# STM32H7RSxx register map
File version: 0.2
CPU: CM7 r0p1, little endian, MPU, FPU, 4 interrupt priority bits
Registers are 32-bit, read-write, reset 0x0 unless marked. A register's access mark holds for its fields unless they carry their own. Offsets are from the block's base; [hi:lo] are bit positions; lines under a group give offsets from that group; 'fields as' and 'values as' point back to an identical list.

## DCMIPP — Digital camera interface pixel pipeline
Base 0x50002000
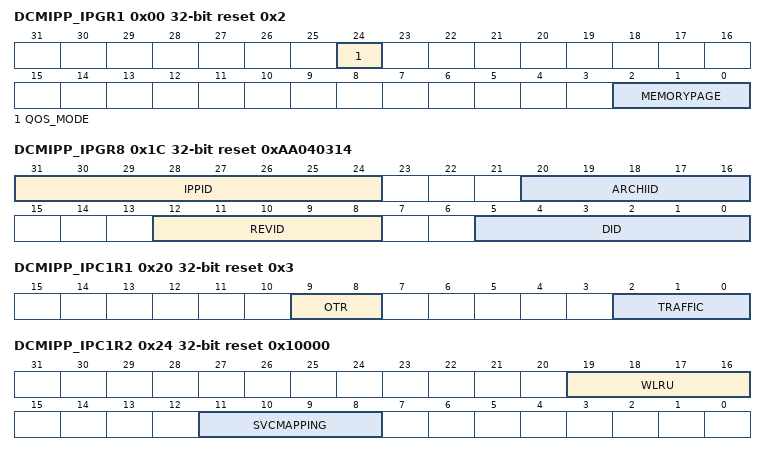
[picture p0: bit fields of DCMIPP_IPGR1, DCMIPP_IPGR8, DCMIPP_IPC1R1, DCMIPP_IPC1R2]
0x00 DCMIPP_IPGR1 reset 0x2 — DCMIPP IP-Plug global register 1
  [24] QOS_MODE — Quality of service Set of functions enabling to build and configure an architecture able to meet bandwidth and latency requirements.
  [2:0] MEMORYPAGE — Memory page size, as power of 2 of 64-byte units:
    0=64 bytes; 1=128 bytes
0x04 DCMIPP_IPGR2 — DCMIPP IP-Plug global register 2
  [0] PSTART — Request to lock the IP-Plug, to allow reconfiguration. PSTART must be reset to 0 after configuration is completed, to restart the IP-Plug.
    0=No lock requested, IP-Plug runs on demand by background HW; 1=Lock requested: IP-Plug freezes shortly (see IDLE bit when lock is active)
0x08 DCMIPP_IPGR3 ro reset 0x1 — DCMIPP IP-Plug global register 3
  [0] IDLE — Status of IP-Plug IDLE is set some time after a request by setting PSTART at 1, and reset by resetting PSTART at 0.
    0=IP-Plug is running (on demand by background HW); 1=IP-Plug is currently locked and can be reconfigured
0x1C DCMIPP_IPGR8 ro reset 0xAA040314 — DCMIPP IP-Plug identification register
  [31:24] IPPID — IP identifier (0xAA)
  [20:16] ARCHIID — Architecture identifier (0x04)
  [12:8] REVID — Revision identifier (0x03)
  [5:0] DID — Division identifier (0x14)
0x20 DCMIPP_IPC1R1 reset 0x3 — DCMIPP IP-Plug Clientx register 1
  [9:8] OTR — Maximum outstanding transactions ... Other values are not allowed.
    0=Disabled. No outstanding transaction limitation (except via FIFO size); 1=Maximum two outstanding transactions ongoing
  [2:0] TRAFFIC — Burst size as power of 2 of 8-byte units Other values: Reserved
    0=8 bytes; 1=16 bytes
0x24 DCMIPP_IPC1R2 reset 0x10000 — DCMIPP IP-Plug Clientx register 2
  [19:16] WLRU — Ratio for WLRU[3:0] arbitration A client gets a portion of the total bandwidth = Ratio(client) / Sum(all ratio) ...
    0=Ratio part = 1; 1=Ratio part = 2
  [11:8] SVCMAPPING — Non-user, must be kept at reset value.
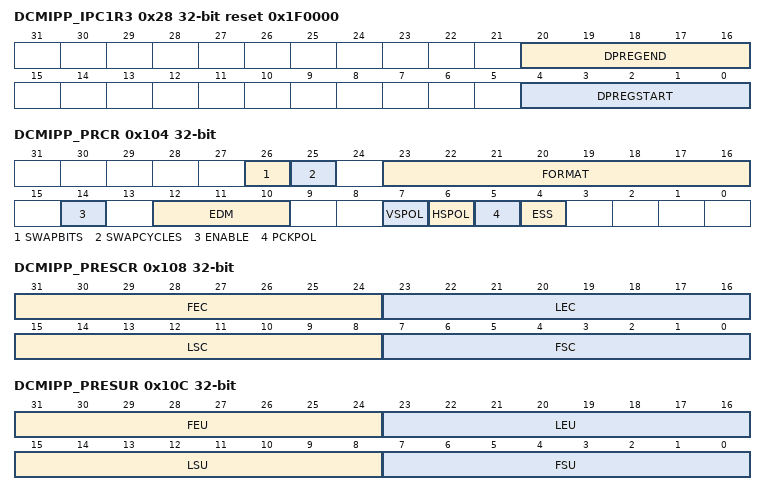
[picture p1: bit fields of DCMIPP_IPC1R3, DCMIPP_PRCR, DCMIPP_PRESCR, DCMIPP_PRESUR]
0x28 DCMIPP_IPC1R3 reset 0x1F0000 — DCMIPP IP-Plug Clientx register 3
  [20:16] DPREGEND — End word (AXI width = 64 bits) of the FIFO of Clientx. The addressed word is included in the FIFO, so that next DPREGSTART is DPREGEND + 1.
  [4:0] DPREGSTART — Start word (AXI width = 64 bits) of the FIFO of Clientx.
0x104 DCMIPP_PRCR — DCMIPP parallel interface control register
  [26] SWAPBITS — Swap LSB vs. MSB within each received component
    0=As received; 1=Swapped MSB vs. LSB
  [25] SWAPCYCLES — Swap data (cycle 0 vs. cycle 1) for pixels received on two cycles The swap must not be activated by software for pixels received in one or three cycles.
    0=Default; 1=Swap active: the data of cycle 1 is used before the data of cycle 0
  [23:16] FORMAT — Other values: data are captured and output as-is only through the data/dump pipeline (for example JPEG or byte input format). The monochrome Y input is inserted in the pipe as YUV pixels, with the U and V components set to neutral, to represent a grey color.
    30=YUV422; 34=RGB565; 36=RGB888 (= YUV444); 42=RAW8; 43=RAW10; 44=RAW12; 45=RAW14; 74=monochrome 8-bit; 75=monochrome 10-bit; 76=monochrome 12-bit; 77=monochrome 14-bit; 90=byte stream (JPEG, compressed video)
  [14] ENABLE — Parallel interface enable The parallel interface configuration registers must be correctly programmed before enabling this bit.
    0=Parallel interface disabled to lower power consumption; 1=Parallel interface enabled
  [12:10] EDM — Extended data mode Other values: Reserved.
    0=Interface captures 8-bit data on every pixel clock; 1=Interface captures 10-bit data on every pixel clock; 2=Interface captures 12-bit data on every pixel clock; 3=Interface captures 14-bit data on every pixel clock; 4=Interface captures 16-bit data on every pixel clock
  [7] VSPOL — Vertical synchronization polarity This bit indicates the level on the VSYNC pin when the data are not valid on the parallel interface.
    0=VSYNC active low; 1=VSYNC active high
  [6] HSPOL — Horizontal synchronization polarity This bit indicates the level on the HSYNC pin when the data are not valid on the parallel interface.
    0=HSYNC active low; 1=HSYNC active high
  [5] PCKPOL — Pixel clock polarity This bit configures the capture edge of the pixel clock
    0=Falling edge active; 1=Rising edge active
  [4] ESS — Embedded synchronization select Valid only for 8-bit parallel data. HSPOL/VSPOL are ignored when this bit is set.
    0=Hardware synchronization data capture (frame/line start/stop) is synchronized with the HSYNC/VSYNC signals; 1=Embedded synchronization data capture is synchronized with synchronization codes embedded in the data flow
0x108 DCMIPP_PRESCR — DCMIPP parallel interface embedded synchronization code register
  [31:24] FEC — Frame end delimiter code This byte specifies the code of the frame end delimiter. The code consists of four bytes in the form of 0xFF, 0x00, 0x00, FEC. If FEC is programmed to 0xFF, all the unused codes (0xFF00 00XY) are interpreted as frame end delimiters.
  [23:16] LEC — Line end delimiter code This byte specifies the code of the line end delimiter. The code consists of four bytes in the form of 0xFF, 0x00, 0x00, LEC.
  [15:8] LSC — Line start delimiter code This byte specifies the code of the line start delimiter. The code consists of four bytes in the form of 0xFF, 0x00, 0x00, LSC.
  [7:0] FSC — Frame start delimiter code This byte specifies the code of the frame start delimiter. The code consists of four bytes in the form of 0xFF, 0x00, 0x00, FSC. If FSC is programmed to 0xFF, no frame start delimiter is detected, but the first occurrence of LSC after an FEC code is interpreted as the start of frame delimiter.
0x10C DCMIPP_PRESUR — DCMIPP parallel interface embedded synchronization unmask register
  [31:24] FEU — Frame end delimiter unmask This byte specifies the mask to be applied to the code of the frame end delimiter.
    0=The corresponding bit in the FEC byte in DCMIPP_ESCR is masked while comparing the frame end delimiter with the received data; 1=The corresponding bit in the FEC byte in DCMIPP_ESCR is compared while comparing the frame end delimiter with the received data
  [23:16] LEU — Line end delimiter unmask This byte specifies the mask to be applied to the code of the line end delimiter.
    0=The corresponding bit in the LEC byte in DCMIPP_ESCR is masked while comparing the line end delimiter with the received data; 1=The corresponding bit in the LEC byte in DCMIPP_ESCR is compared while comparing the line end delimiter with the received data
  [15:8] LSU — Line start delimiter unmask This byte specifies the mask to be applied to the code of the line start delimiter.
    0=The corresponding bit in the LSC byte in DCMIPP_ESCR is masked while comparing the line start delimiter with the received data; 1=The corresponding bit in the LSC byte in DCMIPP_ESCR is compared while comparing the line start delimiter with the received data
  [7:0] FSU — Frame start delimiter unmask This byte specifies the mask to be applied to the code of the frame start delimiter.
    0=The corresponding bit in the FSC byte in DCMIPP_ESCR is masked while comparing the frame start delimiter with the received data; 1=The corresponding bit in the FSC byte in DCMIPP_ESCR is compared while comparing the frame start delimiter with the received data
0x1F4 DCMIPP_PRIER — DCMIPP parallel interface interrupt enable register
  [6] ERRIE — Synchronization error interrupt enable This bit is available only in embedded synchronization mode.
    0=No interrupt generation; 1=An interrupt is generated if the embedded synchronization codes are not received in the correct order
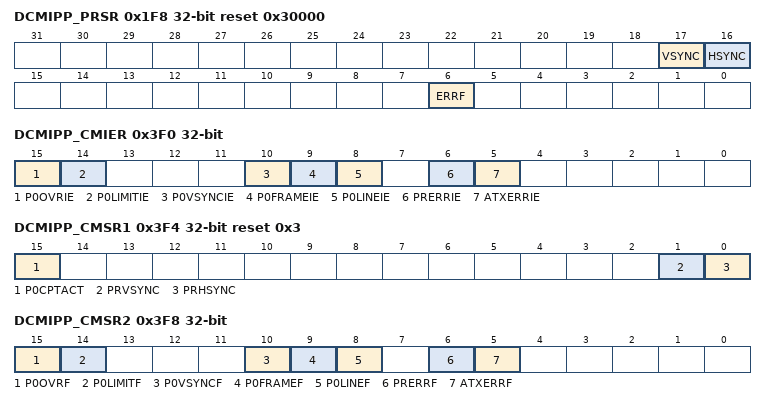
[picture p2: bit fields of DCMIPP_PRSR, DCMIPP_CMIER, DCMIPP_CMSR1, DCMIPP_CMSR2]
0x1F8 DCMIPP_PRSR ro reset 0x30000 — DCMIPP parallel interface status register
  [17] VSYNC — This bit gives the state of the VSYNC pin with the correct programmed polarity if ENABLE bit is set into the DCMIPP_PRCR register and if the pixel clock is received. It is set during the blanking period whatever the polarity selected in VPOL bit, and cleared otherwise. When embedded synchronization codes are used: In case of embedded synchronization, this bit is meaningful only if the CAPTURE bit in DCMIPP_CR is set.
    0=Active frame; 1=Synchronization between frames
  [16] HSYNC — This bit gives the state of the HSYNC pin with the correct programmed polarity if ENABLE bit is set into the DCMIPP_PRCR register and if the pixel clock is received. It is set during the blanking period whatever the polarity selected in HPOL bit, and cleared otherwise. When embedded synchronization codes are used: In case of embedded synchronization, this bit is meaningful only if the CAPTURE bit in DCMIPP_CR is set.
    0=Active line; 1=Synchronization between lines
  [6] ERRF — Synchronization error raw interrupt status This bit is valid only in the embedded synchronization mode. It is cleared by writing a ‘1’ to the CERRF bit in DCMIPP_PRFCR. This bit is available only in embedded synchronization mode.
    0=No synchronization error detected; 1=Embedded synchronization characters are not received in the correct order
0x1FC DCMIPP_PRFCR wo — DCMIPP parallel interface interrupt clear register
  [6] CERRF — Synchronization error interrupt status clear Writing a ‘1’ into this bit clears the ERRF bit in DCMIPP_PRSR. This bit is available only in embedded synchronization mode.
0x204 DCMIPP_CMCR wo — DCMIPP common configuration register
  [4] CFC — Clear frame counter When this bit is set, the frame counter associated to a pipe is cleared. It resets DCMIPP_CMFRCR register. This bit is always read at 0.
0x208 DCMIPP_CMFRCR ro — DCMIPP common frame counter register
  [31:0] FRMCNT — Frame counter, read-only, loops around. Incremented following VSYNC detection mapped to the pipe configured into bits PSFC[1:0] of the DCMIPP_CMCR register. The counter is cleared using the CRC bit in the DCMIPP_CMCR register.
0x3F0 DCMIPP_CMIER — DCMIPP common interrupt enable register
  [all] fields
    0=No interrupt generation; 1=An interrupt is generated
  [15] P0OVRIE — Overrun interrupt enable for Pipe0
  [14] P0LIMITIE — Limit interrupt enable for Pipe0
  [10] P0VSYNCIE — Vertical sync interrupt enable for Pipe0
  [9] P0FRAMEIE — Frame capture complete interrupt enable for Pipe0
  [8] P0LINEIE — Multi-line capture complete interrupt enable for Pipe0
  [6] PRERRIE — Limit interrupt enable for the parallel Interface
  [5] ATXERRIE — AXI transfer error interrupt enable for IP-Plug
0x3F4 DCMIPP_CMSR1 ro reset 0x3 — DCMIPP common status register 1
  [15] P0CPTACT — Active frame capture (active from start-of-frame to frame complete) for Pipe0
    0=No capture currently active; 1=Capture currently active
  [1] PRVSYNC — This bit gives the state of the VSYNC pin with the correct programmed polarity on the parallel interface if ENABLE bit is set into the DCMIPP_PRCR register and if the pixel clock is received. It is set during the blanking period whatever the polarity selected in VPOL bit of the DCMIPP_PRCR register, and cleared otherwise. When embedded synchronization codes are used, the meaning of this bit is the following: In case of embedded synchronization, this bit is meaningful only if the CAPTURE bit in the DCMIPP_PRCR register is set.
    0=Active frame; 1=Synchronization between frames
  [0] PRHSYNC — This bit gives the state of the HSYNC pin with the correct programmed polarity on the parallel interface if ENABLE bit is set into the DCMIPP_PRCR register and if the pixel clock is received. It is set during the blanking period whatever the polarity selected in HPOL bit of the DCMIPP_PRCR register, and cleared otherwise. When embedded synchronization codes are used the meaning of this bit is the following: In case of embedded synchronization, this bit is meaningful only if the CAPTURE bit in the DCMIPP_PRCR register is set.
    0=Active line; 1=Synchronization between lines
0x3F8 DCMIPP_CMSR2 ro — DCMIPP common status register 2
  [15] P0OVRF — Overrun raw interrupt status for Pipe0 This bit is cleared by writing a ‘1’ to the CP0OVRF bit in the DCMIPP_CMFCR register.
    0=No data buffer overrun occurred; 1=A data buffer overrun occurred and this frame data are corrupted
  [14] P0LIMITF — Limit raw interrupt status for Pipe0 This bit is set when the data counter DCMIPP_P0DCCNT reaches its maximum value DCMIPP_P0DCLIMIT. It is cleared by writing a ‘1’ to the CP0LIMITF bit in the DCMIPP_CMFCR register.
  [10] P0VSYNCF — VSYNC raw interrupt status for Pipe0 This bit is set when the VSYNC signal changes from the inactive state to the active state. In the case of embedded synchronization, this bit is set only if the CAPTURE bit is set in DCMIPP_CR. It is cleared by writing a ‘1’ to the CP0VSYNCF bit in the DCMIPP_CMFCR register.
  [9] P0FRAMEF — Frame capture completed raw interrupt status for Pipe0 This bit is set when all data of a frame or window have been captured. In case of a cropped window, this bit is set at the end of line of the last line in the crop, even if the captured frame is empty (for example window cropped outside the frame). This bit is cleared by writing a ‘1’ to the CP0FRAMEF bit in the DCMIPP_CMFCR register.
    0=No capture or ongoing capture; 1=All data of a frame have been captured
  [8] P0LINEF — Multi-line capture completed raw interrupt status for Pipe0 This bit is set when one/more lines have been completed. The periodicity of LINEF event is configured by LINEMULT bits into DCMIPP_P0PPCR register. When reaching end of frame, this event is triggered out to allow software action even if the LINEMULT value set is not a multiple of the total lines frame. In the case of embedded synchronization, this bit is set only if the CAPTURE bit in the DCMIPP_CR register is set. It is cleared by writing a ‘1’ to the CP0LINEF bit in the DCMIPP_CMFCR register.
  [6] PRERRF — Synchronization error raw interrupt status for the parallel interface. This bit is valid only in the embedded synchronization mode. It is cleared by writing a ‘1’ to the CPRERRF bit in the DCMIPP_CMFCR register. This bit is available only in embedded synchronization mode.
    values as DCMIPP_PRSR.ERRF
  [5] ATXERRF — AXI transfer error interrupt status flag for the IP-Plug. This bit is cleared by writing a ‘1’ to CATXERRF bit in the DCMIPP_CMFCR register.
    0=No AXI transfer error detected; 1=AXI transfer error occurred on an AXI client. This bit signals an error on a client without any specific hardware action, the software must handle the situation (normally used when debugging software application code).
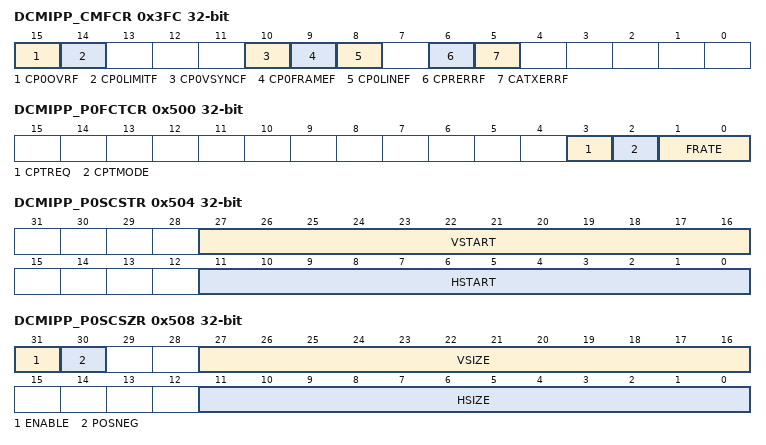
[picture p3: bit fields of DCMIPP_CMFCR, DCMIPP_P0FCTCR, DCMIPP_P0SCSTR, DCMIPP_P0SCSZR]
0x3FC DCMIPP_CMFCR wo — DCMIPP common interrupt clear register
  [15] CP0OVRF — Overrun interrupt status clear Writing a ‘1’ into this bit clears the P0OVRF bit in the DCMIPP_CMSR2 register
  [14] CP0LIMITF — limit interrupt status clear Writing a ‘1’ into this bit clears P0LIMITF in the DCMIPP_CMSR2 register
  [10] CP0VSYNCF — Vertical synchronization interrupt status clear Writing a ‘1’ into this bit clears the P0VSYNCF bit in the DCMIPP_CMSR2 register.
  [9] CP0FRAMEF — Frame capture complete interrupt status clear Writing a ‘1’ into this bit clears the P0FRAMEF bit in the DCMIPP_CMSR2 register.
  [8] CP0LINEF — Multi-line capture complete interrupt status clear Writing a ‘1’ into this bit clears P0LINEF in the DCMIPP_CMSR2 register
  [6] CPRERRF — Synchronization error interrupt status clear Writing a ‘1’ into this bit clears the PRERRF bit in the DCMIPP_CMSR2 register. This bit is available only in embedded synchronization mode.
  [5] CATXERRF — AXI transfer error interrupt status clear Writing a ‘1’ into this bit clears the ATXERRF bit in the DCMIPP_CMSR2 register.
0x404 DCMIPP_P0FSCR — DCMIPP Pipe0 flow selection configuration register
  [31] PIPEN — Activation of PipeN Note: This bit is not shadowed, differently from all other bits in this register.
    0=Pipe disabled; 1=Pipe enabled, can start capturing with CPTMODE, CPTREQ, CPTACK
0x500 DCMIPP_P0FCTCR — DCMIPP Pipe0 flow control configuration register
  [3] CPTREQ — Capture requested When PIPEN = 1 and when the CPTREQ is set to 1 the pipe waits for the first VSync, and automatically starts a capture and sets CPTACT = 1 to mention it. In Snapshot mode the CPTREQ bit is automatically cleared at the start of the first received frame. In Continuous grab mode, the capture remains active and CPTREQ = 1 until the software clears CPTREQ: the capture stops and CPTACT is reset at the end of the ongoing frame. The DCMI and pipe configuration registers must be correctly programmed before enabling this bit.
    0=Capture not requested for next frame; 1=Capture requested for next frame
  [2] CPTMODE — Capture mode
    0=Continuous grab mode - The received data are transferred into the destination memory through the AXI master; 1=Snapshot mode (single frame) - Once activated, the interface waits for the start of frame, and then transfers a single frame through the AXI master. At the end of the frame, the CPTACT bit is automatically reset.
  [1:0] FRATE — Frame capture rate control These bits define the frequency of frame capture. They are meaningful only in Continuous grab mode, ignored in Snapshot mode.
    0=All frames are captured; 1=One out of two frames captured (50% bandwidth reduction); 2=One out of four frames captured (75% bandwidth reduction); 3=One out of eight frames captured (87% bandwidth reduction)
0x504 DCMIPP_P0SCSTR — DCMIPP Pipe0 stat/crop start register
  [27:16] VSTART — Vertical start, from 0 to 4094 pixels high
  [11:0] HSTART — Horizontal start, from 0 to 4094 words wide
0x508 DCMIPP_P0SCSZR — DCMIPP Pipe0 stat/crop size register
  [31] ENABLE — This bit is set and cleared by software. if POSNEG = 0, the data inside the rectangle area are transmitted (it can correspond to a statistical data removal, or as a crop feature in a data valid image area). if POSNEG = 1, the data outside of the rectangle area are transmitted (it can correspond to a statistical data extraction, rejecting all data inside the window). This bit must be kept cleared if the input format is JPEG, to avoid unpredictable behavior of the pipe.
    0=Bypass. All the data are computed, if the statistic data are sent within the frame, they are sent to the processing pipe as pixels data.; 1=Enable. Depending on bit POSNEG value, the rectangle defined by VSIZE, HSIZE, VSTART and HSTART can be used to extract or to remove some data (statistical extraction or removal, or basic 2D crop features).
  [30] POSNEG — This bit is set and cleared by software. It has a meaning only if ENABLE bit is set.
    0=Positive area, the rectangle defined by VSIZE, HSIZE, and VSTART, HSTART; 1=Negative area, the area excluding the rectangle defined by VSIZE, HSIZE, and VSTART, HSTART
  [27:16] VSIZE — Vertical size, from 0 to 4094 pixels high If the value is maintained at 0 when enabling the crop by means of ENABLE bit, the crop operation is not performed on vertical direction.
  [11:0] HSIZE — Horizontal size, from 0 to 4094 word wide (data 32-bit) If the value is maintained at 0 when enabling the crop by means of ENABLE bit, the crop operation is not performed on horizontal direction.
0x5B0 DCMIPP_P0DCCNTR ro — DCMIPP Pipe0 dump counter register
  [25:0] CNT — Number of data dumped during the frame. The size of the data is expressed in bytes. It counts only the data selected by means of the CROP 2D function. The counter saturates at 0x3FFFFFF. Granularity is 32-bit for all the formats except for the byte stream formats (for example JPEG) having byte granularity.
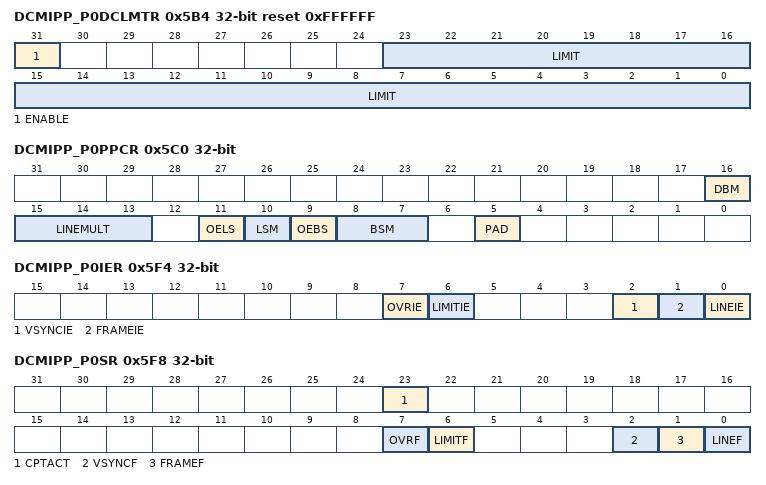
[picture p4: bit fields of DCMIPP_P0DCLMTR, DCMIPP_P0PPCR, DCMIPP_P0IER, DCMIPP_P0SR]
0x5B4 DCMIPP_P0DCLMTR reset 0xFFFFFF — DCMIPP Pipe0 dump limit register
  [31] ENABLE
    0=Disabled, no check on the amount of 32-bit words transmitted; 1=Enabled, check done versus limit
  [23:0] LIMIT — Maximum number of 32-bit data that can be dumped during a frame, after the crop 2D operation.
0x5C0 DCMIPP_P0PPCR — DCMIPP Pipe0 pixel packer configuration register
  [16] DBM — Double buffer mode This bit is set and cleared by software.
    0=No double buffer mode activated. Pipe0 always dumps to memory address set by DCMIPP_P0PPM0AR1.; 1=Double buffer mode activated. Dump address location switches from DCMIPP_P0PPM0AR1 to DCMIPP_P0PPM0AR2 alternatively on each frame.
  [15:13] LINEMULT — Amount of capture completed lines for LINE event and interrupt
    0=Event after one line; 1=Event after two lines; 2=Event after four lines; 3=Event after eight lines; 4=Event after sixteen lines; 5=Event after 32 lines; 6=Event after 64 lines; 7=Event after 128 lines
  [11] OELS — Odd/even line select (line select start) This bit works in conjunction with LSM field (LSM = 1).
    0=Interface captures first line after the frame start, second one is dropped; 1=Interface captures second line from the frame start, first one is dropped
  [10] LSM — Line select mode
    0=Interface captures all received lines; 1=Interface captures one line out of two
  [9] OEBS — Odd/even byte select (byte select start) This bit works in conjunction with BSM field (BSM ≠ 00)
    0=Interface captures the first data (byte or double byte) from the frame/line start, the second one is dropped; 1=Interface captures the second data (byte or double byte) from the frame/line start, the first one is dropped
  [8:7] BSM — Byte select mode Modes 10 and 11 work only with EDM [2:0] = 000 into the DCMIPP_PRCR register.
    0=Interface captures all received data; 1=Interface captures 1 data out of 2; 2=Interface captures one byte out of four; 3=Interface captures two bytes out of four
  [5] PAD — Pad mode for monochrome and raw Bayer 10/12/14 bpp: MSB vs. LSB alignment.
    0=Aligns on LSB (and pads null bits on MSB), for backward compatibility with former DCMI; 1=Aligns on MSB (and pads null bits on LSB), for better ease of software or GPU
0x5C4 DCMIPP_P0PPM0AR1 — DCMIPP Pipe0 pixel packer Memory0 address register 1
  [31:0] M0A — Memory0 address Base address of memory area 0, to whom data are written. It is assumed to be a multiple of 16, hence its bits 3:0 are always at 0x0.
0x5C8 DCMIPP_P0PPM0AR2 — DCMIPP Pipe0 pixel packer Memory0 address register 2
  fields as DCMIPP_P0PPM0AR1
0x5F4 DCMIPP_P0IER — DCMIPP Pipe0 interrupt enable register
  [7] OVRIE — Overrun interrupt enable
    0=No interrupt generation; 1=An interrupt is generated if the AXI master is unable to transfer the last data before new data (32-bit) are received
  [6] LIMITIE — Limit interrupt enable
    0=No interrupt generation when the limit is reached; 1=An interrupt is generated when the limit is reached
  [2] VSYNCIE — VSYNC interrupt enable
    0=No interrupt generation; 1=An interrupt is generated on each VSYNC (captured or not)
  [1] FRAMEIE — Frame capture completed interrupt enable
    0=No interrupt generation; 1=An interrupt is generated after the full capture of a cropped frame
  [0] LINEIE — Multi-line capture completed interrupt enable
    0=No interrupt generation when the line is received; 1=An interrupt is generated after the full capture of a group of lines (or last line reached)
0x5F8 DCMIPP_P0SR ro — DCMIPP Pipe0 status register
  [23] CPTACT — Capture immediate status This bit is automatically reset at the end of frame capture complete event (after all the data of that frame have been captured and the IP-Plug has started to emit the last burst on the AXI, usually before the next VSync).
    0=Capture currently inactive; 1=Capture currently active
  [7] OVRF — Overrun raw interrupt status This bit is cleared by writing a ‘1’ to the COVRF bit in the DCMIPP_P0FCR register.
    values as DCMIPP_CMSR2.P0OVRF
  [6] LIMITF — Limit raw interrupt status This bit is set when the data counter DCMIPP_PxDCCNTR reaches its maximum value DCMIPP_PxDCLIMITR. It is cleared by writing a ‘1’ to the CLIMITF bit in the DCMIPP_P0FCR register.
  [2] VSYNCF — VSYNC raw interrupt status This bit is set when the VSYNC signal changes from the inactive state to the active state. In case of embedded synchronization, this bit is set only if the CAPTURE bit is set in DCMIPP_CR. It is cleared by writing a ‘1’ to the CVSYNCF bit in the DCMIPP_P0FCR register.
  [1] FRAMEF — Frame capture completed raw interrupt status This bit is set when all data of a frame or window have been captured. In case of a cropped window, this bit is set at the end of line of the last line in the crop. It is set even if the captured frame is empty (for example window cropped outside the frame). This bit is cleared by writing a ‘1’ to the CFRAMEF bit in DCMIPP_P0FCR.
    values as DCMIPP_CMSR2.P0FRAMEF
  [0] LINEF — Multi-line capture completed raw interrupt status This bit is set when one/more lines have been completed. For the JPEG mode, this bit is raised at the end of the frame. The periodicity of LINEF event is configured by LINEMULT bits into DCMIPP_P0PPCR register. When reaching end of frame, this event is triggered out to allow software action even if the LINEMULT value set is not a multiple of the total lines frame. In case of embedded synchronization, this bit is set only if the CAPTURE bit in the DCMIPP_CR register is set. It is cleared by writing a ‘1’ to the CLINEF bit in the DCMIPP_P0FCR register.
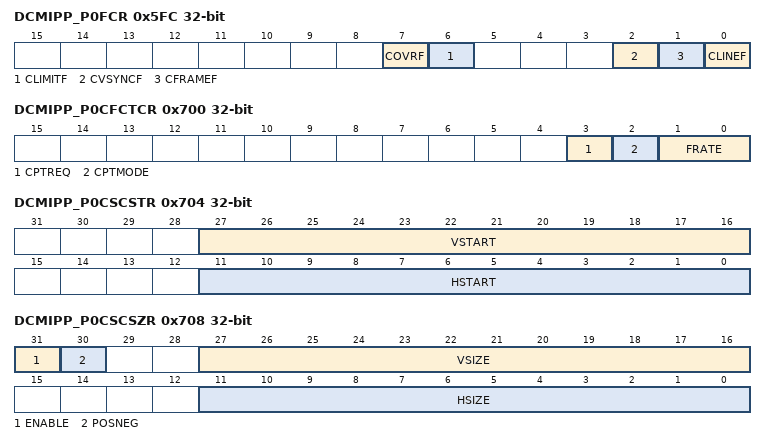
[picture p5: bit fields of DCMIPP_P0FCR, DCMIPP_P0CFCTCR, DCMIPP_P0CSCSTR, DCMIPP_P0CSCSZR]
0x5FC DCMIPP_P0FCR wo — DCMIPP Pipe0 interrupt clear register
  [7] COVRF — Overrun interrupt status clear Writing a ‘1’ into this bit clears the OVRF bit in the DCMIPP_P0SR register.
  [6] CLIMITF — limit interrupt status clear Writing a ‘1’ into this bit clears LIMITF in the DCMIPP_P0SR register.
  [2] CVSYNCF — Vertical synchronization interrupt status clear Writing a ‘1’ into this bit clears the VSYNCF bit in the DCMIPP_P0SR register.
  [1] CFRAMEF — Frame capture complete interrupt status clear Writing a ‘1’ into this bit clears the FRAMEF bit in the DCMIPP_P0SR register.
  [0] CLINEF — Multi-line capture complete interrupt status clear Writing a ‘1’ into this bit clears LINEF in the DCMIPP_P0SR register.
0x700 DCMIPP_P0CFCTCR ro — DCMIPP Pipe0 current flow control configuration register
  [3] CPTREQ — Capture requested When PIPEN = 1, and when the CPTREQ is set to 1 the pipe waits for the first VSync, and automatically starts a capture and sets CPTACT = 1 to mention it. In Snapshot mode the CPTREQ bit is automatically cleared at the start of the first frame received. In continuous grab mode the capture remains active and CPTREQ = 1, until the software clears CPTREQ: the capture stops and CPTACT is reset at the end of the ongoing frame. The DCMI and pipe configuration registers must be correctly programmed before enabling this bit.
    values as DCMIPP_P0FCTCR.CPTREQ
  [2] CPTMODE — Capture mode
    0=Continuous grab mode - The received data are transferred into the destination memory through the AXI master; 1=Snapshot mode (single frame) - Once activated, the interface waits for the start of frame, and then transfers a single frame through the AXI master. At the end of the frame the CPTACT bit is automatically reset.
  [1:0] FRATE — Frame capture rate control These bits define the frequency of frame capture. They are meaningful only in Continuous grab mode, ignored in Snapshot mode.
    values as DCMIPP_P0FCTCR.FRATE
0x704 DCMIPP_P0CSCSTR ro — DCMIPP Pipe0 current stat/crop start register
  [27:16] VSTART — Current vertical start, from 0 to 4094 pixels high
  [11:0] HSTART — Current horizontal start, from 0 to 4094 words wide
0x708 DCMIPP_P0CSCSZR ro — DCMIPP Pipe0 current stat/crop size register
  [31] ENABLE — Current value of the ENABLE bit if POSNEG = 0, the data inside the rectangle area are transmitted (can correspond to a statistical data removal, or as a crop feature in a data valid image area). if POSNEG = 1, the data outside of the rectangle area are transmitted (can correspond to a statistical data extraction, rejecting all data inside the window)
    0=Bypass. All data are computed, if the statistics data are sent within the frame, they are sent to the processing pipe as pixels data.; 1=Enable: Depending on bit POSNEG value, the rectangle defined by the VSIZE, HSIZE, VSTART, HSTART can be used to extract or to remove certain amount of data (statistical extraction or removal, or basic 2D crop features)
  [30] POSNEG — Current value of the POSNEG bit This bit has a meaning only if ENABLE bit is set.
    0=Positive area. The rectangle defined by VSIZE,HSIZE, and VSTART, HSTART is the active area.; 1=Negative area. The active area is the area excluding the rectangle defined by VSIZE, HSIZE, and VSTART, HSTART.
  [27:16] VSIZE — Current vertical size, from 0 to 4094 pixels high. If the value is maintained at 0 when enabling the crop by means of the ENABLE bit, the value is forced internally at 0xFFE which is the maximum value.
  [11:0] HSIZE — Current horizontal size, from 0 to 4094 word wide (data 32-bit). If the value is maintained at 0 when enabling the crop by means of the ENABLE bit, the value is forced internally at 0xFFE, which is the maximum value.
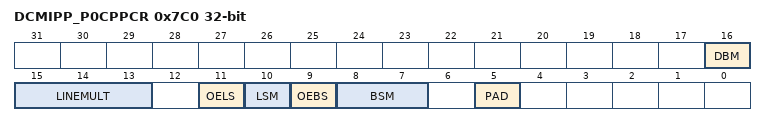
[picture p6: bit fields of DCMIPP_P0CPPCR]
0x7C0 DCMIPP_P0CPPCR ro — DCMIPP Pipe0 current pixel packer configuration register
  [16] DBM — Double buffer mode
    0=No double buffer mode activated. Pipe0 is always dump to memory address set by DCMIPP_P0PPM0AR1 register; 1=Double buffer mode activated. Dump address location switches from DCMIPP_P0PPM0AR1 register to DCMIPP_P0PPM0AR2 register alternatively on each frame.
  [15:13] LINEMULT — Current amount of capture completed lines for LINE event and interrupt
    0=Event after every line; 1=Event after two lines; 2=Event after four lines; 3=Event after eight lines; 4=Event after sixteen lines; 5=Event after 32 lines; 6=Event after 64 lines; 7=Event after 128 lines
  [11] OELS — Current odd/even line select (ine select start) This bit works in conjunction with LSM field (LSM = 1)
    0=Interface captures the first line after the frame start, the second one is dropped; 1=Interface captures the second line from the frame start, the first one is dropped
  [10] LSM — Current Line select mode
    values as DCMIPP_P0PPCR.LSM
  [9] OEBS — Current odd/even byte select (byte select start) This bit works in conjunction with BSM field (BSM ≠ 00)
    values as DCMIPP_P0PPCR.OEBS
  [8:7] BSM — Current Byte select mode Modes 10 and 11 work only with EDM [2:0] = 000 into the DCMIPP_PRCR register.
    0=Interface captures all received data; 1=Interface captures one data out of two; 2=Interface captures one byte out of four; 3=Interface captures two bytes out of four
  [5] PAD — Current Pad mode for monochrome and raw Bayer 10/12/14 bpp: MSB vs. LSB alignment
    values as DCMIPP_P0PPCR.PAD
0x7C4 DCMIPP_P0CPPM0AR1 ro — DCMIPP Pipe0 current pixel packer Memory0 address register 1
  [31:0] M0A — Memory0 address Base address of the current memory area 0, to whom data are written. It is assumed to be a multiple of 16, hence its bits 3:0 are always at 0x0.
0x7C8 DCMIPP_P0CPPM0AR2 ro — DCMIPP Pipe0 current pixel packer Memory0 address register 2
  fields as DCMIPP_P0CPPM0AR1
